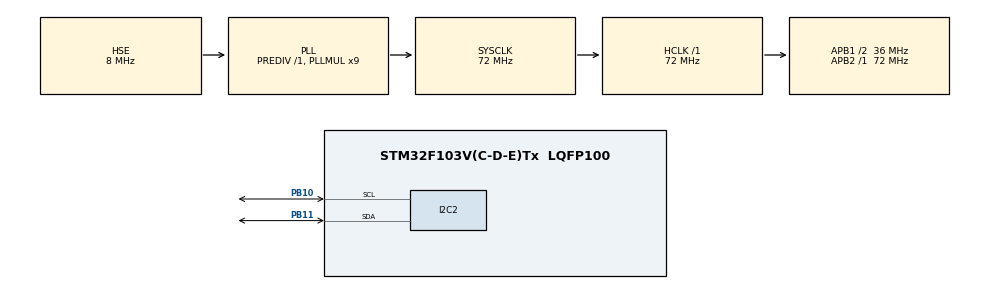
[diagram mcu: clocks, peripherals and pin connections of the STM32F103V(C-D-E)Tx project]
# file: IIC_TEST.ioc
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I2C2.I2C_Mode=I2C_Standard
Mcu.Family=STM32F1
Mcu.Name=STM32F103V(C-D-E)Tx
Mcu.Package=LQFP100
NVIC.PriorityGroup=NVIC_PRIORITYGROUP_4
OSC_IN.Mode=HSE-External-Oscillator
OSC_IN.Signal=RCC_OSC_IN
OSC_OUT.Mode=HSE-External-Oscillator
OSC_OUT.Signal=RCC_OSC_OUT
PA13.Mode=Serial_Wire
PA13.Signal=SYS_JTMS-SWDIO
PA14.Mode=Serial_Wire
PA14.Signal=SYS_JTCK-SWCLK
PB10.Mode=I2C
PB10.Signal=I2C2_SCL
PB11.Mode=I2C
PB11.Signal=I2C2_SDA
ProjectManager.HeapSize=0x200
ProjectManager.StackSize=0x400
ProjectManager.TargetToolchain=MDK-ARM V5.32
RCC.AHBFreq_Value=72000000
RCC.APB1CLKDivider=RCC_HCLK_DIV2
RCC.APB1Freq_Value=36000000
RCC.APB1TimFreq_Value=72000000
RCC.APB2Freq_Value=72000000
RCC.APB2TimFreq_Value=72000000
RCC.HCLKFreq_Value=72000000
RCC.PLLMUL=RCC_PLL_MUL9
RCC.PLLSourceVirtual=RCC_PLLSOURCE_HSE
RCC.SYSCLKFreq_VALUE=72000000
RCC.SYSCLKSource=RCC_SYSCLKSOURCE_PLLCLK
RCC.USBFreq_Value=72000000
board=custom

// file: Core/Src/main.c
/* USER CODE BEGIN Header */
/* 注: 文件信息见顶部规范文件头 (个人编程代码规范) */
/* USER CODE END Header */
#include "main.h"
#include "i2c.h"
#include "gpio.h"

/* USER CODE BEGIN PD */
#define I2C_SCAN_INTERVAL_MS   500U  /* 每次探测的间隔(ms) */
#define I2C_PROBE_ADDR         0x50U /* 探测用的7位从机地址 0xA0>>1 */
#define I2C_PROBE_TIMEOUT_MS   10U   /* 单次探测超时(ms) */
/* USER CODE END PD */

/* USER CODE BEGIN PV */
static uint32_t g_last_probe_tick = 0U;  /* 上次探测时刻 */
/* USER CODE END PV */

void SystemClock_Config(void);

int main(void)
{

  /* MCU Configuration--------------------------------------------------------*/

  /* Reset of all peripherals, Initializes the Flash interface and the Systick. */
  HAL_Init();

  /* Configure the system clock */
  SystemClock_Config();

  /* Initialize all configured peripherals */
  MX_GPIO_Init();
  MX_I2C2_Init();
  /* USER CODE BEGIN 2 */
  /* F1的I2C模拟滤波器上电默认开启, 无需额外配置 */
  /* USER CODE END 2 */

  /* Infinite loop */
  while (1)
  {

    /* USER CODE BEGIN 3 */
    /* 周期性向0x50发START+地址探测:
     * 无从设备时第9个时钟NACK, HAL_I2C_IsDeviceReady返回HAL_ERROR,
     * 这是预期现象 —— 逻辑分析仪/示波器上能看到完整START+ADDR时序 */
    if ((uint32_t)(HAL_GetTick() - g_last_probe_tick) >= I2C_SCAN_INTERVAL_MS)
    {
      g_last_probe_tick = HAL_GetTick();
      (void)HAL_I2C_IsDeviceReady(&hi2c2, I2C_PROBE_ADDR << 1,
                                  1U, I2C_PROBE_TIMEOUT_MS);
      /* 返回值故意丢弃: NACK是本测试预期, 不进Error_Handler */
    }
  }
  /* USER CODE END 3 */
}

void SystemClock_Config(void)
{
  RCC_OscInitTypeDef RCC_OscInitStruct = {0};
  RCC_ClkInitTypeDef RCC_ClkInitStruct = {0};

  /** Initializes the RCC Oscillators according to the specified parameters
  * in the RCC_OscInitTypeDef structure.
  */
  RCC_OscInitStruct.OscillatorType = RCC_OSCILLATORTYPE_HSE;
  RCC_OscInitStruct.HSEState = RCC_HSE_ON;
  RCC_OscInitStruct.HSEPredivValue = RCC_HSE_PREDIV_DIV1;
  RCC_OscInitStruct.HSIState = RCC_HSI_ON;
  RCC_OscInitStruct.PLL.PLLState = RCC_PLL_ON;
  RCC_OscInitStruct.PLL.PLLSource = RCC_PLLSOURCE_HSE;
  RCC_OscInitStruct.PLL.PLLMUL = RCC_PLL_MUL9;
  if (HAL_RCC_OscConfig(&RCC_OscInitStruct) != HAL_OK)
  {
    Error_Handler();
  }

  /** Initializes the CPU, AHB and APB buses clocks
  */
  RCC_ClkInitStruct.ClockType = RCC_CLOCKTYPE_HCLK|RCC_CLOCKTYPE_SYSCLK
                              |RCC_CLOCKTYPE_PCLK1|RCC_CLOCKTYPE_PCLK2;
  RCC_ClkInitStruct.SYSCLKSource = RCC_SYSCLKSOURCE_PLLCLK;
  RCC_ClkInitStruct.AHBCLKDivider = RCC_SYSCLK_DIV1;
  RCC_ClkInitStruct.APB1CLKDivider = RCC_HCLK_DIV2;
  RCC_ClkInitStruct.APB2CLKDivider = RCC_HCLK_DIV1;

  if (HAL_RCC_ClockConfig(&RCC_ClkInitStruct, FLASH_LATENCY_2) != HAL_OK)
  {
    Error_Handler();
  }
}

void Error_Handler(void)
{
  __disable_irq();
  while (1)
  {
  }
}
